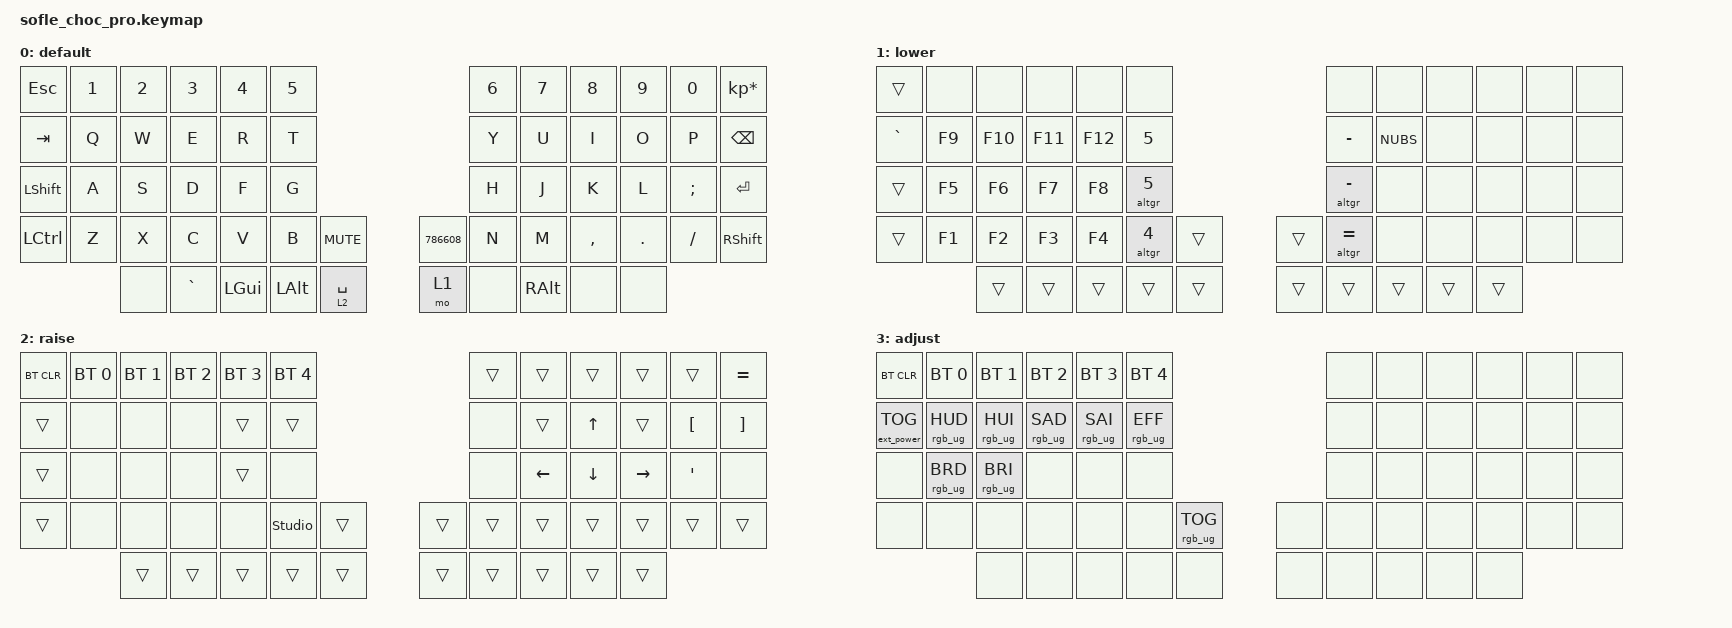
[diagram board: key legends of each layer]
/*
* Copyright (c) 2020 The ZMK Contributors
*
* SPDX-License-Identifier: MIT
*/

#include <behaviors.dtsi>
#include <dt-bindings/zmk/keys.h>
#include <dt-bindings/zmk/bt.h>
#include <dt-bindings/zmk/rgb.h>
#include <dt-bindings/zmk/ext_power.h>

#define BASE 0
#define LOWER 1
#define RAISE 2
#define ADJUST 3

/ {

  macros {
    altgr: altgr {
      compatible = "zmk,behavior-macro-one-param";
      #binding-cells = <1>;
      wait-ms = <15>;
      tap-ms = <15>;
      bindings
        = <&macro_press &kp RALT>
        , <&macro_param_1to1>
        , <&macro_tap &kp MACRO_PLACEHOLDER>
        , <&macro_release &kp RALT>
        ;
    };
  };

  // Activate ADJUST layer by pressing raise and lower
  conditional_layers {
    compatible = "zmk,conditional-layers";
    adjust_layer {
      if-layers = <LOWER RAISE>;
      then-layer = <ADJUST>;
    };
  };

  keymap {
    compatible = "zmk,keymap";

    default_layer {
      display-name = "default";
      // ------------------------------------------------------------------------------------------------------------
      // |   `   |  1  |  2  |  3   |  4   |  5   |                   |  6   |  7    |  8    |  9   |   0   |   `   |
      // |  ESC  |  Q  |  W  |  E   |  R   |  T   |                   |  Y   |  U    |  I    |  O   |   P   | BKSPC |
      // |  TAB  |  A  |  S  |  D   |  F   |  G   |                   |  H   |  J    |  K    |  L   |   ;   |   '   |
      // | SHIFT |  Z  |  X  |  C   |  V   |  B   |  MUTE  |  | PLAY  |  N   |  M    |  ,    |  .   |   /   | SHIFT |
      //               | GUI | ALT  | CTRL | LOWER|  ENTER |  | SPACE | RAISE| CTRL  | ALT   | GUI  |
      bindings = <
        &kp ESC        
        &kp N1         
        &kp N2         
        &kp N3         
        &kp N4         
        &kp N5         
        &kp N6         
        &kp N7         
        &kp N8         
        &kp N9         
        &kp N0         
        &kp KP_ASTERISK
        &kp TAB        
        &kp Q          
        &kp W          
        &kp E          
        &kp R          
        &kp T          
        &kp Y          
        &kp U          
        &kp I          
        &kp O          
        &kp P          
        &kp BSPC       
        &kp LSHFT      
        &kp A          
        &kp S          
        &kp D          
        &kp F          
        &kp G          
        &kp H          
        &kp J          
        &kp K          
        &kp L          
        &kp SEMI       
        &kp RET        
        &kp LCTL       
        &kp Z          
        &kp X          
        &kp C          
        &kp V          
        &kp B          
        &kp C_MUTE     
        &kp 786608     
        &kp N          
        &kp M          
        &kp COMMA      
        &kp DOT        
        &kp FSLH       
        &kp RSHFT      
        &none          
        &kp GRAVE      
        &kp LGUI       
        &kp LALT       
        &lt 2 SPACE    
        &mo 1          
        &none          
        &kp RALT       
        &none          
        &none          
      >;

      sensor-bindings = <&inc_dec_kp C_VOL_DN C_VOL_UP &inc_dec_kp C_PREV C_NEXT>;
    };

    lower_layer {
      display-name = "lower";
      // ------------------------------------------------------------------------------------------------------------
      // |       |  F1 |  F2 |  F3  |  F4  |  F5  |                   |  F6  |  F7   |  F8   |  F9  |  F10  |  F11  |
      // |   `   |  1  |  2  |  3   |  4   |  5   |                   |  6   |  7    |  8    |  9   |   0   |  F12  |
      // |       |  !  |  @  |  #   |  $   |  %   |                   |  ^   |  &    |  *    |  (   |   )   |   |   |
      // |       |  =  |  -  |  +   |  {   |  }   |        |  |       |  [   |  ]    |  ;    |  :   |   \   |       |
      //               |     |      |      |      |        |  |       |      |       |       |      |
      bindings = <
        &trans       
        &none        
        &none        
        &none        
        &none        
        &none        
        &none        
        &none        
        &none        
        &none        
        &none        
        &none        
        &kp GRAVE    
        &kp F9       
        &kp F10      
        &kp F11      
        &kp F12      
        &kp N5       
        &kp MINUS    
        &kp NUBS     
        &none        
        &none        
        &none        
        &none        
        &trans       
        &kp F5       
        &kp F6       
        &kp F7       
        &kp F8       
        &altgr N5   
        &altgr MINUS
        &none        
        &none        
        &none        
        &none        
        &none        
        &trans       
        &kp F1       
        &kp F2       
        &kp F3       
        &kp F4       
        &altgr N4   
        &trans       
        &trans       
        &altgr EQUAL
        &none        
        &none        
        &none        
        &none        
        &none        
        &trans       
        &trans       
        &trans       
        &trans       
        &trans       
        &trans       
        &trans       
        &trans       
        &trans       
        &trans       
      >;

      sensor-bindings = <&inc_dec_kp C_VOL_DN C_VOL_UP &inc_dec_kp C_PREV C_NEXT>;
    };

    raise_layer {
      display-name = "raise";
      // ------------------------------------------------------------------------------------------------------------
      // | BTCLR | BT1  | BT2  |  BT3  |  BT4  |  BT5 |                |      |      |       |      |       |       |
      // |       | INS  | PSCR | GUI   |       |      |                | PGUP |      |   ^   |      |       |       |
      // |       | ALT  | CTRL | SHIFT |       | CAPS |                | PGDN |   <- |   v   |  ->  |  DEL  | BKSPC |
      // |       | UNDO | CUT  | COPY  | PASTE | STUD |      |  |      |      |      |       |      |       |       |
      //                |      |       |       |      |      |  |      |      |      |       |      |
    bindings = <
      &bt BT_CLR    
      &bt BT_SEL 0  
      &bt BT_SEL 1  
      &bt BT_SEL 2  
      &bt BT_SEL 3  
      &bt BT_SEL 4  
      &trans        
      &trans        
      &trans        
      &trans        
      &trans        
      &kp EQUAL     
      &trans        
      &none         
      &none         
      &none         
      &trans        
      &trans        
      &none         
      &trans        
      &kp UP        
      &trans        
      &kp LBKT      
      &kp RBKT      
      &trans        
      &none         
      &none         
      &none         
      &trans        
      &none         
      &none         
      &kp LEFT      
      &kp DOWN      
      &kp RIGHT     
      &kp SQT       
      &none         
      &trans        
      &none         
      &none         
      &none         
      &none         
      &studio_unlock
      &trans        
      &trans        
      &trans        
      &trans        
      &trans        
      &trans        
      &trans        
      &trans        
      &trans        
      &trans        
      &trans        
      &trans        
      &trans        
      &trans        
      &trans        
      &trans        
      &trans        
      &trans        
    >;

      sensor-bindings = <&inc_dec_kp C_VOL_DN C_VOL_UP &inc_dec_kp C_PREV C_NEXT>;
    };

    adjust_layer {
      // ----------------------------------------------------------------------------------------------------------------------------
      // | BTCLR  |  BT1    |  BT2    |   BT3   |   BT4   |   BT5   |                  |      |      |       |      |       |       |
      // | EXTPWR | RGB_HUD | RGB_HUI | RGB_SAD | RGB_SAI | RGB_EFF |                  |      |      |       |      |       |       |
      // |        | RGB_BRD | RGB_BRI |         |         |         |                  |      |      |       |      |       |       |
      // |        |         |         |         |         |         | RGB_TOG | |      |      |      |       |      |       |       |
      //                    |         |         |         |         |         | |      |      |      |       |      |
      display-name = "adjust";
      bindings = <
        &bt BT_CLR        &bt BT_SEL 0    &bt BT_SEL 1    &bt BT_SEL 2    &bt BT_SEL 3    &bt BT_SEL 4                            &none &none &none &none &none &none
        &ext_power EP_TOG &rgb_ug RGB_HUD &rgb_ug RGB_HUI &rgb_ug RGB_SAD &rgb_ug RGB_SAI &rgb_ug RGB_EFF                         &none &none &none &none &none &none
        &none             &rgb_ug RGB_BRD &rgb_ug RGB_BRI &none           &none           &none                                   &none &none &none &none &none &none
        &none             &none           &none           &none           &none           &none            &rgb_ug RGB_TOG &none  &none &none &none &none &none &none
        &none           &none           &none           &none            &none           &none  &none &none &none &none
      >;
    };
  };
};
